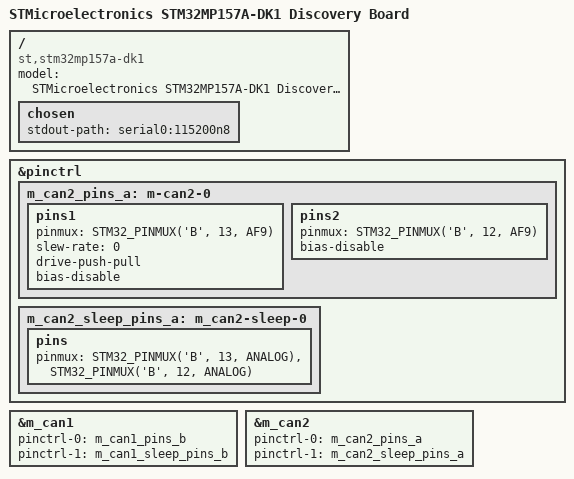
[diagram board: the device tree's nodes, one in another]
// SPDX-License-Identifier: (GPL-2.0+ OR BSD-3-Clause)
/*
 * Copyright (C) STMicroelectronics 2019 - All Rights Reserved
 * Author: Alexandre Torgue <alexandre.torgue@st.com> for STMicroelectronics.
 */

/dts-v1/;

#include "stm32mp157.dtsi"
#include "stm32mp15xa.dtsi"
#include "stm32mp15-pinctrl.dtsi"
#include "stm32mp15xxac-pinctrl.dtsi"
#include "stm32mp15xx-dkx.dtsi"

/ {
	model = "STMicroelectronics STM32MP157A-DK1 Discovery Board";
	compatible = "st,stm32mp157a-dk1", "st,stm32mp157";

	chosen {
		stdout-path = "serial0:115200n8";
	};
};
&pinctrl {
m_can2_pins_a: m-can2-0 {
    pins1 {
	pinmux = <STM32_PINMUX('B', 13, AF9)>; /* CAN2_TX */
	slew-rate = <0>;
	drive-push-pull;
	bias-disable;
    };
    pins2 {
	pinmux = <STM32_PINMUX('B', 12, AF9)>; /* CAN2_RX */
	bias-disable;
    };
};

m_can2_sleep_pins_a: m_can2-sleep-0 {
    pins {
	pinmux = <STM32_PINMUX('B', 13, ANALOG)>, /* CAN2_TX */
	     <STM32_PINMUX('B', 12, ANALOG)>; /* CAN2_RX */
    };
};
};
&m_can1 {
	pinctrl-names = "default", "sleep";
	pinctrl-0 = <&m_can1_pins_b>;
	pinctrl-1 = <&m_can1_sleep_pins_b>;
	status = "okay";
};

&m_can2 {
	pinctrl-names = "default", "sleep";
	pinctrl-0 = <&m_can2_pins_a>;
	pinctrl-1 = <&m_can2_sleep_pins_a>;
	status = "okay";
};
